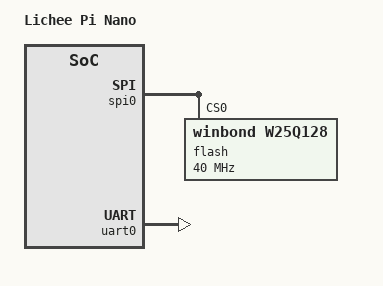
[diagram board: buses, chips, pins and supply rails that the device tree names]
// SPDX-License-Identifier: (GPL-2.0+ OR X11)
/*
 * Copyright 2018 Icenowy Zheng <icenowy@aosc.io>
 */

/dts-v1/;
#include "suniv.dtsi"

#include <dt-bindings/gpio/gpio.h>

/ {
	model = "Lichee Pi Nano";
	compatible = "licheepi,licheepi-nano", "allwinner,suniv-f1c100s",
		     "allwinner,suniv";

	aliases {
		serial0 = &uart0;
		spi0 = &spi0;
	};

	chosen {
		stdout-path = "serial0:115200n8";
	};
};

&spi0 {
	pinctrl-names = "default";
	pinctrl-0 = <&spi0_pins_a>;
	status = "okay";
    spi-max-frequency = <50000000>;

	flash@0 {
		#address-cells = <1>;
		#size-cells = <1>;
		compatible = "winbond,w25q128", "jedec,spi-nor";
		reg = <0>;
		spi-max-frequency = <40000000>;
	};
};

&uart0 {
	pinctrl-names = "default";
	pinctrl-0 = <&uart0_pins_a>;
	status = "okay";
};
